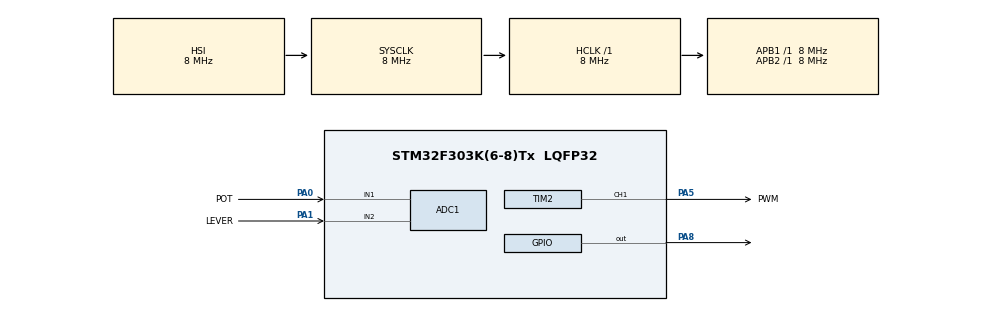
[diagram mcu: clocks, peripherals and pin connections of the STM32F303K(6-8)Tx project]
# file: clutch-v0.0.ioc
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ADC1.Channel-0\#ChannelRegularConversion=ADC_CHANNEL_1
ADC1.Channel-1\#ChannelRegularConversion=ADC_CHANNEL_2
ADC1.ContinuousConvMode=ENABLE
ADC1.DMAContinuousRequests=ENABLE
ADC1.NbrOfConversion=2
ADC1.NbrOfConversionFlag=1
ADC1.Offset-0\#ChannelRegularConversion=0
ADC1.Offset-1\#ChannelRegularConversion=0
ADC1.OffsetNumber-0\#ChannelRegularConversion=ADC_OFFSET_NONE
ADC1.OffsetNumber-1\#ChannelRegularConversion=ADC_OFFSET_NONE
ADC1.Rank-0\#ChannelRegularConversion=1
ADC1.Rank-1\#ChannelRegularConversion=2
ADC1.SamplingTime-0\#ChannelRegularConversion=ADC_SAMPLETIME_61CYCLES_5
ADC1.SamplingTime-1\#ChannelRegularConversion=ADC_SAMPLETIME_61CYCLES_5
ADC1.SubFamily=STM32F303x8
ADC1.master=1
Dma.ADC1.0.Direction=DMA_PERIPH_TO_MEMORY
Dma.ADC1.0.Instance=DMA1_Channel1
Dma.ADC1.0.MemDataAlignment=DMA_MDATAALIGN_HALFWORD
Dma.ADC1.0.MemInc=DMA_MINC_ENABLE
Dma.ADC1.0.Mode=DMA_CIRCULAR
Dma.ADC1.0.PeriphDataAlignment=DMA_PDATAALIGN_HALFWORD
Dma.ADC1.0.PeriphInc=DMA_PINC_DISABLE
Dma.ADC1.0.Priority=DMA_PRIORITY_LOW
Dma.Request0=ADC1
Mcu.Family=STM32F3
Mcu.Name=STM32F303K(6-8)Tx
Mcu.Package=LQFP32
NVIC.DMA1_Channel1_IRQn=true\:0\:0\:false\:false\:true\:false\:true\:true
NVIC.PriorityGroup=NVIC_PRIORITYGROUP_4
NVIC.TIM6_DAC1_IRQn=true\:0\:0\:false\:false\:true\:true\:true\:true
PA0.GPIO_Label=POT
PA0.Mode=IN1-Single-Ended
PA0.Signal=ADC1_IN1
PA1.GPIO_Label=LEVER
PA1.Mode=IN2-Single-Ended
PA1.Signal=ADC1_IN2
PA5.GPIO_Label=PWM
PA5.Signal=S_TIM2_CH1_ETR
PA8.PinState=GPIO_PIN_SET
PA8.Signal=GPIO_Output
ProjectManager.HeapSize=0x200
ProjectManager.StackSize=0x400
ProjectManager.TargetToolchain=STM32CubeIDE
RCC.ADC12PRES=RCC_ADC12PLLCLK_DIV8
RCC.AHBFreq_Value=8000000
RCC.APB1Freq_Value=8000000
RCC.APB2Freq_Value=8000000
RCC.CortexFreq_Value=8000000
RCC.HSE_VALUE=8000000
RCC.HSI_VALUE=8000000
RCC.PLLMUL=RCC_PLL_MUL4
RCC.SYSCLKFreq_VALUE=8000000
SH.S_TIM2_CH1_ETR.0=TIM2_CH1,PWM Generation1 CH1
TIM2.Channel-PWM\ Generation1\ CH1=TIM_CHANNEL_1
TIM2.Period=100 - 1
TIM2.Prescaler=8 - 1
TIM6.Period=100 - 1
TIM6.Prescaler=100 - 1
VP_TIM6_VS_ClockSourceINT.Mode=Enable_Timer
board=custom

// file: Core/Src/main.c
/* USER CODE BEGIN Header */
/**
  ******************************************************************************
  * @file           : main.c
  * @brief          : Main program body
  ******************************************************************************
  * @attention
  *
  * Copyright (c) 2022 STMicroelectronics.
  * All rights reserved.
  *
  * This software is licensed under terms that can be found in the LICENSE file
  * in the root directory of this software component.
  * If no LICENSE file comes with this software, it is provided AS-IS.
  *
  ******************************************************************************
  */
/* USER CODE END Header */
#include "main.h"

/* USER CODE BEGIN PD */
#define BUFFER_LENGTH 2
/* USER CODE END PD */

 ADC_HandleTypeDef hadc1;
DMA_HandleTypeDef hdma_adc1;

TIM_HandleTypeDef htim2;
TIM_HandleTypeDef htim6;

/* USER CODE BEGIN PV */
uint16_t ADC_values[BUFFER_LENGTH];
/* USER CODE END PV */

void SystemClock_Config(void);
static void MX_GPIO_Init(void);
static void MX_DMA_Init(void);
static void MX_ADC1_Init(void);
static void MX_TIM2_Init(void);
static void MX_TIM6_Init(void);

int main(void)
{
  /* USER CODE BEGIN 1 */
  uint16_t timer_val;
  uint16_t timer_count;
  /* USER CODE END 1 */

  /* MCU Configuration--------------------------------------------------------*/

  /* Reset of all peripherals, Initializes the Flash interface and the Systick. */
  HAL_Init();

  /* Configure the system clock */
  SystemClock_Config();

  /* Initialize all configured peripherals */
  MX_GPIO_Init();
  MX_DMA_Init();
  MX_ADC1_Init();
  MX_TIM2_Init();
  MX_TIM6_Init();
  /* USER CODE BEGIN 2 */
  HAL_ADC_Start_DMA(&hadc1, (uint16_t *)ADC_values, BUFFER_LENGTH);

  HAL_TIM_Base_Start(&htim2); // TIM2 Start
  HAL_TIM_PWM_Start(&htim2, TIM_CHANNEL_1); // PWM Start on TIM2
  HAL_TIM_Base_Start_IT(&htim6); // PID Sampling timer start

  timer_val = __HAL_TIM_GET_COUNTER(&htim6);
  /* USER CODE END 2 */

  /* Infinite loop */
  while (1)
  {

    /* USER CODE BEGIN 3 */
	timer_count = __HAL_TIM_GET_COUNTER(&htim6) - timer_val;

	if(timer_count >= 10) {
	  HAL_GPIO_TogglePin(GPIOA, GPIO_PIN_8);
	  timer_val = __HAL_TIM_GET_COUNTER(&htim6);
	}
  }
  /* USER CODE END 3 */
}

void SystemClock_Config(void)
{
  RCC_OscInitTypeDef RCC_OscInitStruct = {0};
  RCC_ClkInitTypeDef RCC_ClkInitStruct = {0};
  RCC_PeriphCLKInitTypeDef PeriphClkInit = {0};

  /** Initializes the RCC Oscillators according to the specified parameters
  * in the RCC_OscInitTypeDef structure.
  */
  RCC_OscInitStruct.OscillatorType = RCC_OSCILLATORTYPE_HSI;
  RCC_OscInitStruct.HSIState = RCC_HSI_ON;
  RCC_OscInitStruct.HSICalibrationValue = RCC_HSICALIBRATION_DEFAULT;
  RCC_OscInitStruct.PLL.PLLState = RCC_PLL_ON;
  RCC_OscInitStruct.PLL.PLLSource = RCC_PLLSOURCE_HSI;
  RCC_OscInitStruct.PLL.PLLMUL = RCC_PLL_MUL4;
  if (HAL_RCC_OscConfig(&RCC_OscInitStruct) != HAL_OK)
  {
    Error_Handler();
  }

  /** Initializes the CPU, AHB and APB buses clocks
  */
  RCC_ClkInitStruct.ClockType = RCC_CLOCKTYPE_HCLK|RCC_CLOCKTYPE_SYSCLK
                              |RCC_CLOCKTYPE_PCLK1|RCC_CLOCKTYPE_PCLK2;
  RCC_ClkInitStruct.SYSCLKSource = RCC_SYSCLKSOURCE_HSI;
  RCC_ClkInitStruct.AHBCLKDivider = RCC_SYSCLK_DIV1;
  RCC_ClkInitStruct.APB1CLKDivider = RCC_HCLK_DIV1;
  RCC_ClkInitStruct.APB2CLKDivider = RCC_HCLK_DIV1;

  if (HAL_RCC_ClockConfig(&RCC_ClkInitStruct, FLASH_LATENCY_0) != HAL_OK)
  {
    Error_Handler();
  }
  PeriphClkInit.PeriphClockSelection = RCC_PERIPHCLK_ADC12;
  PeriphClkInit.Adc12ClockSelection = RCC_ADC12PLLCLK_DIV8;
  if (HAL_RCCEx_PeriphCLKConfig(&PeriphClkInit) != HAL_OK)
  {
    Error_Handler();
  }
}

static void MX_ADC1_Init(void)
{

  ADC_MultiModeTypeDef multimode = {0};
  ADC_ChannelConfTypeDef sConfig = {0};

  /** Common config
  */
  hadc1.Instance = ADC1;
  hadc1.Init.ClockPrescaler = ADC_CLOCK_ASYNC_DIV1;
  hadc1.Init.Resolution = ADC_RESOLUTION_12B;
  hadc1.Init.ScanConvMode = ADC_SCAN_ENABLE;
  hadc1.Init.ContinuousConvMode = ENABLE;
  hadc1.Init.DiscontinuousConvMode = DISABLE;
  hadc1.Init.ExternalTrigConvEdge = ADC_EXTERNALTRIGCONVEDGE_NONE;
  hadc1.Init.ExternalTrigConv = ADC_SOFTWARE_START;
  hadc1.Init.DataAlign = ADC_DATAALIGN_RIGHT;
  hadc1.Init.NbrOfConversion = 2;
  hadc1.Init.DMAContinuousRequests = ENABLE;
  hadc1.Init.EOCSelection = ADC_EOC_SINGLE_CONV;
  hadc1.Init.LowPowerAutoWait = DISABLE;
  hadc1.Init.Overrun = ADC_OVR_DATA_OVERWRITTEN;
  if (HAL_ADC_Init(&hadc1) != HAL_OK)
  {
    Error_Handler();
  }

  /** Configure the ADC multi-mode
  */
  multimode.Mode = ADC_MODE_INDEPENDENT;
  if (HAL_ADCEx_MultiModeConfigChannel(&hadc1, &multimode) != HAL_OK)
  {
    Error_Handler();
  }

  /** Configure Regular Channel
  */
  sConfig.Channel = ADC_CHANNEL_1;
  sConfig.Rank = ADC_REGULAR_RANK_1;
  sConfig.SingleDiff = ADC_SINGLE_ENDED;
  sConfig.SamplingTime = ADC_SAMPLETIME_61CYCLES_5;
  sConfig.OffsetNumber = ADC_OFFSET_NONE;
  sConfig.Offset = 0;
  if (HAL_ADC_ConfigChannel(&hadc1, &sConfig) != HAL_OK)
  {
    Error_Handler();
  }

  /** Configure Regular Channel
  */
  sConfig.Channel = ADC_CHANNEL_2;
  sConfig.Rank = ADC_REGULAR_RANK_2;
  if (HAL_ADC_ConfigChannel(&hadc1, &sConfig) != HAL_OK)
  {
    Error_Handler();
  }

}

static void MX_TIM2_Init(void)
{

  TIM_MasterConfigTypeDef sMasterConfig = {0};
  TIM_OC_InitTypeDef sConfigOC = {0};

  htim2.Instance = TIM2;
  htim2.Init.Prescaler = 8 - 1;
  htim2.Init.CounterMode = TIM_COUNTERMODE_UP;
  htim2.Init.Period = 100 - 1;
  htim2.Init.ClockDivision = TIM_CLOCKDIVISION_DIV1;
  htim2.Init.AutoReloadPreload = TIM_AUTORELOAD_PRELOAD_DISABLE;
  if (HAL_TIM_PWM_Init(&htim2) != HAL_OK)
  {
    Error_Handler();
  }
  sMasterConfig.MasterOutputTrigger = TIM_TRGO_RESET;
  sMasterConfig.MasterSlaveMode = TIM_MASTERSLAVEMODE_DISABLE;
  if (HAL_TIMEx_MasterConfigSynchronization(&htim2, &sMasterConfig) != HAL_OK)
  {
    Error_Handler();
  }
  sConfigOC.OCMode = TIM_OCMODE_PWM1;
  sConfigOC.Pulse = 0;
  sConfigOC.OCPolarity = TIM_OCPOLARITY_HIGH;
  sConfigOC.OCFastMode = TIM_OCFAST_DISABLE;
  if (HAL_TIM_PWM_ConfigChannel(&htim2, &sConfigOC, TIM_CHANNEL_1) != HAL_OK)
  {
    Error_Handler();
  }
  HAL_TIM_MspPostInit(&htim2);

}

static void MX_TIM6_Init(void)
{

  TIM_MasterConfigTypeDef sMasterConfig = {0};

  htim6.Instance = TIM6;
  htim6.Init.Prescaler = 100 - 1;
  htim6.Init.CounterMode = TIM_COUNTERMODE_UP;
  htim6.Init.Period = 100 - 1;
  htim6.Init.AutoReloadPreload = TIM_AUTORELOAD_PRELOAD_DISABLE;
  if (HAL_TIM_Base_Init(&htim6) != HAL_OK)
  {
    Error_Handler();
  }
  sMasterConfig.MasterOutputTrigger = TIM_TRGO_RESET;
  sMasterConfig.MasterSlaveMode = TIM_MASTERSLAVEMODE_DISABLE;
  if (HAL_TIMEx_MasterConfigSynchronization(&htim6, &sMasterConfig) != HAL_OK)
  {
    Error_Handler();
  }

}

static void MX_DMA_Init(void)
{

  /* DMA controller clock enable */
  __HAL_RCC_DMA1_CLK_ENABLE();

  /* DMA interrupt init */
  /* DMA1_Channel1_IRQn interrupt configuration */
  HAL_NVIC_SetPriority(DMA1_Channel1_IRQn, 0, 0);
  HAL_NVIC_EnableIRQ(DMA1_Channel1_IRQn);

}

static void MX_GPIO_Init(void)
{
  GPIO_InitTypeDef GPIO_InitStruct = {0};

  /* GPIO Ports Clock Enable */
  __HAL_RCC_GPIOA_CLK_ENABLE();

  /*Configure GPIO pin Output Level */
  HAL_GPIO_WritePin(GPIOA, GPIO_PIN_8, GPIO_PIN_SET);

  /*Configure GPIO pin : PA8 */
  GPIO_InitStruct.Pin = GPIO_PIN_8;
  GPIO_InitStruct.Mode = GPIO_MODE_OUTPUT_PP;
  GPIO_InitStruct.Pull = GPIO_NOPULL;
  GPIO_InitStruct.Speed = GPIO_SPEED_FREQ_LOW;
  HAL_GPIO_Init(GPIOA, &GPIO_InitStruct);

}

void Error_Handler(void)
{
  __disable_irq();
  while (1)
  {
  }
}
